VERSION ""

NS_ :

BS_:
BU_:
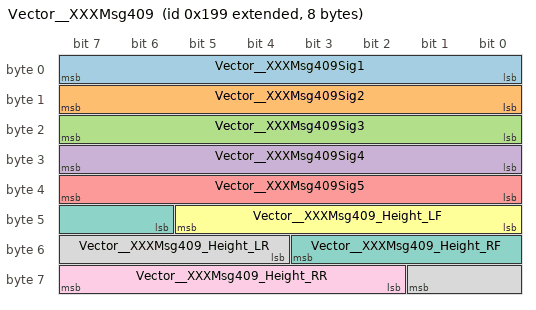
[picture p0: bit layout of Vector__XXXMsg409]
BO_ 2147484057 Vector__XXXMsg409: 8 Vector__XXX
   SG_ Vector__XXXMsg409Sig1 : 0|8@1+ (1,0) [0|1] "" Vector__XXX
   SG_ Vector__XXXMsg409Sig2 : 8|8@1+ (1,0) [0|1] "" Vector__XXX
   SG_ Vector__XXXMsg409Sig3 : 16|8@1+ (1,0) [0|1] "" Vector__XXX
   SG_ Vector__XXXMsg409Sig4 : 24|8@1+ (1,0) [0|1] "" Vector__XXX
   SG_ Vector__XXXMsg409Sig5 : 32|8@1+ (1,0) [0|1] "" Vector__XXX
   SG_ Vector__XXXMsg409_Height_LF : 40|6@1+ (1,0) [0|1] "tbd" Vector__XXX
   SG_ Vector__XXXMsg409_Height_RF : 46|6@1+ (1,0) [0|1] "tbd" Vector__XXX
   SG_ Vector__XXXMsg409_Height_LR : 52|6@1+ (1,0) [0|1] "tbd" Vector__XXX
   SG_ Vector__XXXMsg409_Height_RR : 58|6@1+ (1,0) [0|1] "tbd" Vector__XXX

BO_ 2147484173 Vector__XXXMsg525: 8 Vector__XXX
   SG_ Vector__XXXMsg525Sig352 : 36|2@1+ (5,0) [0|15] "Selected" Vector__XXX

BA_DEF_ BO_ "GenMsgBackgroundColor" STRING ;
BA_DEF_ BO_ "GenMsgForegroundColor" STRING ;
BA_DEF_DEF_ "GenMsgBackgroundColor" "#ffffff";
BA_DEF_DEF_ "GenMsgForegroundColor" "#000000";
VAL_ 2147484173 Vector__XXXMsg525Sig352 0 "Very_High" 1 "High" 2 "Medium" 3 "Low";
